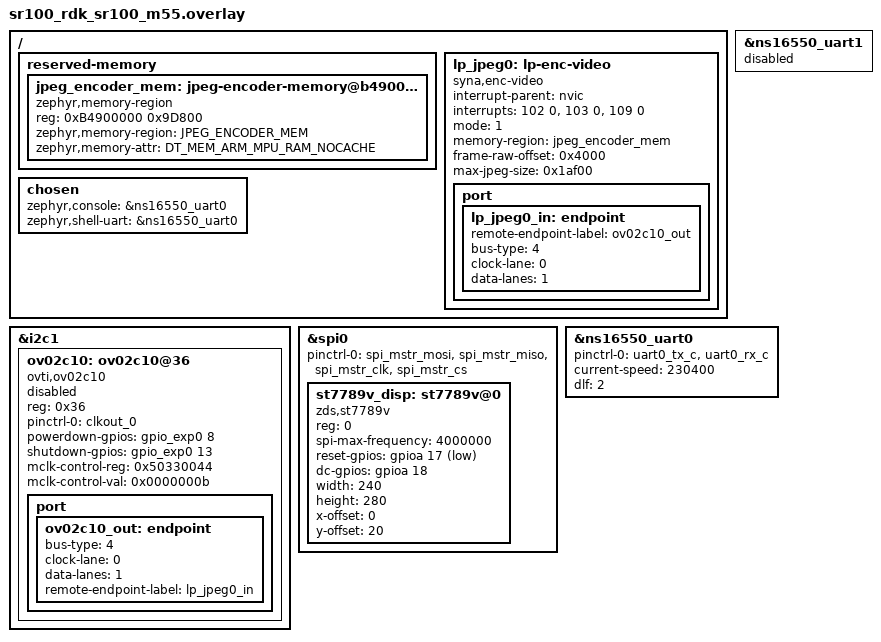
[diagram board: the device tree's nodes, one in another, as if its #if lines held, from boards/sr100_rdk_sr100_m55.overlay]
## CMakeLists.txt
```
cmake_minimum_required(VERSION 3.20.0)
list(APPEND DTS_ROOT ${CMAKE_CURRENT_SOURCE_DIR})
find_package(Zephyr REQUIRED HINTS $ENV{ZEPHYR_BASE})
project(camera_jpeg_encode)

target_sources(app PRIVATE
	src/main.c
	src/tft_still.c
	src/tjpgd.c
)
target_include_directories(app PRIVATE src)
```

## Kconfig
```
# Copyright (c) 2026 Synaptics Incorporated
# SPDX-License-Identifier: Apache-2.0
#
# Lab C4: camera -> hardware JPEG encoder. Based verbatim on the SDK's
# samples/drivers/video/enc sample (live sensor mode, mode=0).

mainmenu "Camera JPEG Encode Lab (SR110)"

source "Kconfig.zephyr"

menu "Camera JPEG Encode Lab"

endmenu
```

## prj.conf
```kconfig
CONFIG_CONSOLE=y
CONFIG_PRINTK=y
CONFIG_LOG=y
CONFIG_LOG_MODE_IMMEDIATE=y
# Avoid Kconfig warnings from board defaults pulling in I2C shell options.
CONFIG_I2C_SHELL=n
CONFIG_FPU=y
CONFIG_I2C=y
CONFIG_GPIO=y
CONFIG_PINCTRL=y
CONFIG_VIDEO=y
CONFIG_VIDEO_SYNA_ENC=y
CONFIG_VIDEO_SYNA_MIPI=n
CONFIG_VIDEO_INIT_PRIORITY=90

# Two 128 KiB buffers + overhead (give headroom).
CONFIG_VIDEO_BUFFER_POOL_HEAP_SIZE=524288

CONFIG_MAIN_STACK_SIZE=4096

# TFT still preview (ST7789V3 raw-SPI driver, reused from Lab C3) - SPI0
# for the panel, GPIO for reset/dc pins. Console is moved to UART0 alt
# pins by the board overlay because SPI0 shares pads with UART1 (see
# the lab doc) - same tradeoff as Lab C3.
CONFIG_SPI=y
```

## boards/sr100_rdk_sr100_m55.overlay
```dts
/*
 * Lab C4 (Camera JPEG Encode + TFT Still Preview) - SR110 (sr100_rdk/sr100/m55)
 *
 * This overlay combines two independent pieces:
 *
 * 1) JPEG hardware encoder pipeline (unchanged from the SDK's
 *    samples/drivers/video/enc sample) - the sensor's CSI output is
 *    connected directly to the encoder node (lp_jpeg0), bypassing
 *    video_syna0 entirely. See the lab doc for why.
 *
 * 2) ST7789V3 TFT over SPI0, reusing Lab C3's confirmed-working
 *    config verbatim, to show the just-encoded JPEG as a still image
 *    after it is decoded back to RGB565 on-device. SPI0's MOSI/MISO
 *    pads are physically shared with the M55's default console UART
 *    (UART1, GPIO23/24), so the console is moved to UART0's alternate
 *    pin group here, exactly like Lab C3 - an external USB-TTL
 *    adapter is needed to see console output (GPIO44/45, J24 pins
 *    13/14).
 */

#include <zephyr/dt-bindings/gpio/gpio.h>
#include <zephyr/dt-bindings/memory-attr/memory-attr-arm.h>

/ {
	reserved-memory {
		#address-cells = <1>;
		#size-cells = <1>;
		ranges;

		jpeg_encoder_mem: jpeg-encoder-memory@b4900000 {
			compatible = "zephyr,memory-region", "mmio-sram";
			reg = <0xB4900000 0x9D800>; /* 0x4000 + 0x7e900 (960x540 RAW8) + 0x1af00 (max JPEG) */
			zephyr,memory-region = "JPEG_ENCODER_MEM";
			zephyr,memory-attr = <DT_MEM_ARM_MPU_RAM_NOCACHE>;
		};
	};

	lp_jpeg0: lp-enc-video {
		compatible = "syna,enc-video";
		status = "okay";
		interrupt-parent = <&nvic>;
		/*
		 * This JPEG encoder flow uses all three underlying IRQ lines:
		 * 102 = FRAME_PROCESSING_DONE, 103 = FMIN1_FRAME_STORED,
		 * 109 = c0 / status events.
		 */
		interrupts = <102 0>, <103 0>, <109 0>;
		interrupt-names = "frame-done", "fmin1-stored", "status";

		/*
		 * Build-time selectable mode.
		 *
		 * Define ENC_MEMORY_INPUT via DTS_EXTRA_CPPFLAGS to switch the
		 * encoder to reserved-memory input mode (static raw in memory).
		 * See "추가로 알면 좋은 내용" in the lab doc for how to try this.
		 */
#ifdef ENC_MEMORY_INPUT
		mode = <1>; /* memory-input mode */
#else
		mode = <0>; /* live sensor mode - default for this lab */
#endif

		/* JPEG encoder reserved memory for raw input and JPEG output buffers. */
		memory-region = <&jpeg_encoder_mem>;
		/* Reserve programmer area (SRSDK default is 0x4000). */
		frame-raw-offset = <0x4000>;

#ifdef ENC_MEMORY_INPUT
		/* Raw input (960x540 = 0x7E900 bytes) starts at frame-raw-offset. */
		max-jpeg-size = <0x1af00>;
#else
		max-jpeg-size = <0x20000>;
#endif

		port {
			lp_jpeg0_in: endpoint {
				remote-endpoint-label = "ov02c10_out";
				bus-type = <4>;
				clock-lane = <0>;
				data-lanes = <1>;
			};
		};

	};
};

	&i2c1 {
		ov02c10: ov02c10@36 {
			compatible = "ovti,ov02c10";
			reg = <0x36>;
#ifdef ENC_MEMORY_INPUT
			status = "disabled";
#else
			status = "okay";
#endif

		pinctrl-0 = <&clkout_0>;
		pinctrl-names = "default";

		powerdown-gpios = <&gpio_exp0 8 GPIO_ACTIVE_HIGH>;
		shutdown-gpios = <&gpio_exp0 13 GPIO_ACTIVE_HIGH>;

		mclk-control-reg = <0x50330044>;
		mclk-control-val = <0x0000000b>;

		port {
			ov02c10_out: endpoint {
				bus-type = <4>;
				clock-lane = <0>;
				data-lanes = <1>;
				remote-endpoint-label = "lp_jpeg0_in";
			};
		};
	};
};

/* --- TFT still-preview display (Lab C3 config, reused verbatim) --- */

&spi0 {
	#address-cells = <1>;
	#size-cells = <0>;
	status = "okay";
	pinctrl-0 = <&spi_mstr_mosi &spi_mstr_miso &spi_mstr_clk &spi_mstr_cs>;
	pinctrl-names = "default";

	st7789v_disp: st7789v@0 {
		compatible = "zds,st7789v";
		reg = <0>;
		spi-max-frequency = <4000000>;
		reset-gpios = <&gpioa 17 GPIO_ACTIVE_LOW>;  /* SoC GPIO17, J24 pin 3 - through level shifter */
		dc-gpios = <&gpioa 18 GPIO_ACTIVE_HIGH>;    /* SoC GPIO18, J24 pin 4 - through level shifter */
		width = <240>;
		height = <280>;
		x-offset = <0>;
		y-offset = <20>;
	};
};

&ns16550_uart1 {
	status = "disabled";
};

&ns16550_uart0 {
	pinctrl-0 = <&uart0_tx_c &uart0_rx_c>;
	pinctrl-names = "default";
	current-speed = <230400>;
	dlf = <2>;
	status = "okay";
};

/ {
	chosen {
		zephyr,console = &ns16550_uart0;
		zephyr,shell-uart = &ns16550_uart0;
	};
};
```

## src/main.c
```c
/*
 * Copyright (c) 2026 Synaptics Incorporated
 *
 * SPDX-License-Identifier: Apache-2.0
 *
 * Lab C4 (Camera JPEG Encode + TFT Still Preview): this is the SDK's
 * samples/drivers/video/enc sample (live sensor mode) with one
 * addition - after the hardware encoder produces a JPEG frame, it is
 * decoded back to RGB565 on-device and shown as a still image on the
 * ST7789V3 TFT (see tft_still.c/.h). Everything else below is
 * unmodified from the original sample.
 */

#include <errno.h>
#include <stdint.h>
#include <string.h>

#include <zephyr/cache.h>
#include <zephyr/device.h>
#include <zephyr/devicetree.h>
#include <zephyr/drivers/video.h>
#include <zephyr/kernel.h>
#include <zephyr/logging/log.h>
#include <zephyr/sys/barrier.h>
#include <zephyr/sys/util.h>
#include <zephyr/video/video.h>

#include "tft_still.h"

LOG_MODULE_REGISTER(enc_video_sample, LOG_LEVEL_INF);

#define TS_LOG(stage) LOG_INF("[TS] %s uptime_ms=%lld", stage, (long long)k_uptime_get())

static inline int64_t app_elapsed_ms(int64_t start_ms)
{
	return k_uptime_get() - start_ms;
}

#define ENC_NODE DT_NODELABEL(lp_jpeg0)

#if !DT_NODE_EXISTS(ENC_NODE)
#error "No lp_jpeg0 devicetree node found"
#endif

#if !DT_NODE_HAS_COMPAT(ENC_NODE, syna_enc_video)
#error "lp_jpeg0 must use compatible = \"syna,enc-video\""
#endif

#define APP_MODE_SENSOR_TO_MEMORY 0U
#define APP_MODE_MEMORY_INPUT 1U
#define APP_PIPELINE_MODE DT_PROP_OR(ENC_NODE, mode, APP_MODE_SENSOR_TO_MEMORY)

#define APP_NUM_BUFS 2U
#define APP_JPEG_BUF_ALIGN 64U
#define APP_MAX_JPEG_BYTES (128U * 1024U)
#define APP_DEQUEUE_TIMEOUT K_SECONDS(5)

#define APP_LIVE_WIDTH 480U
#define APP_LIVE_HEIGHT 270U

#define APP_MEMORY_INPUT_WIDTH 960U
#define APP_MEMORY_INPUT_HEIGHT 540U
#define APP_MEMORY_INPUT_RAW_SIZE ((size_t)APP_MEMORY_INPUT_WIDTH * (size_t)APP_MEMORY_INPUT_HEIGHT)

#define APP_MEM_REGION_PRESENT DT_NODE_HAS_PROP(ENC_NODE, memory_region)
BUILD_ASSERT(APP_MEM_REGION_PRESENT,
	     "JPEG encoder sample requires a memory-region devicetree phandle");
#if APP_MEM_REGION_PRESENT
#define APP_MEM_NODE DT_PHANDLE(ENC_NODE, memory_region)
#define APP_MEM_BASE ((uintptr_t)DT_REG_ADDR(APP_MEM_NODE))
#define APP_MEM_SIZE ((size_t)DT_REG_SIZE(APP_MEM_NODE))
#else
#define APP_MEM_BASE ((uintptr_t)0U)
#define APP_MEM_SIZE 0U
#endif

#define APP_RAW_OFFSET ((size_t)DT_PROP_OR(ENC_NODE, frame_raw_offset, 0))

static uint8_t app_jpeg_buf_mem[APP_NUM_BUFS][APP_MAX_JPEG_BYTES] __aligned(APP_JPEG_BUF_ALIGN);
static struct video_buffer app_jpeg_vbufs[APP_NUM_BUFS];

#if IS_ENABLED(CONFIG_CACHE_MANAGEMENT) && IS_ENABLED(CONFIG_DCACHE)
static void enc_mem_flush(uintptr_t addr, size_t size)
{
	int ret;

	if (size == 0U) {
		return;
	}

	ret = sys_cache_data_flush_range((void *)addr, size);
	if (ret != 0) {
		LOG_WRN("Encoder memory cache flush failed ret=%d addr=%p size=%u",
			ret, (void *)addr, (unsigned int)size);
	}
	barrier_dsync_fence_full();
}
#else
static void enc_mem_flush(uintptr_t addr, size_t size)
{
	ARG_UNUSED(addr);
	ARG_UNUSED(size);
}
#endif

/* Return a human-readable name for the selected run mode. */
static const char *mode_name(uint32_t mode)
{
	if (mode == APP_MODE_MEMORY_INPUT) {
		return "enc-memory-input";
	}

	return "live-to-memory";
}

/* Drain any returned buffers after stopping the stream. */
static void drain_buffers(const struct device *dev)
{
	struct video_buffer *vbuf = NULL;

	while ((video_dequeue(dev, &vbuf, K_NO_WAIT) == 0) && (vbuf != NULL)) {
		vbuf->bytesused = 0U;
	}
}

/* Video helpers */

/*
 * Configure the JPEG output format.
 *
 * The negotiated `jpeg_fmt->size` is the required output-buffer capacity.
 * The actual JPEG size is returned later in `video_buffer.bytesused`.
 */
static int enc_configure(const struct device *enc,
			 struct video_format *jpeg_fmt,
			 uint32_t width,
			 uint32_t height)
{
	int ret;

	*jpeg_fmt = (struct video_format) {
		.type = VIDEO_BUF_TYPE_OUTPUT,
		.pixelformat = VIDEO_PIX_FMT_JPEG,
		.width = width,
		.height = height,
	};

	ret = video_set_format(enc, jpeg_fmt);
	LOG_INF("enc video_set_format ret=%d capacity=%u pitch=%u (%ux%u)",
		ret, jpeg_fmt->size, jpeg_fmt->pitch,
		jpeg_fmt->width, jpeg_fmt->height);
	return ret;
}

/* Allocate and enqueue destination buffers for JPEG output. */
static int jpeg_buffers_queue(const struct device *enc,
			      const struct video_format *jpeg_fmt)
{
	struct video_caps caps = {
		.type = VIDEO_BUF_TYPE_OUTPUT,
	};
	size_t align = APP_JPEG_BUF_ALIGN;
	int ret;

	if ((jpeg_fmt == NULL) || (jpeg_fmt->size > APP_MAX_JPEG_BYTES)) {
		LOG_ERR("JPEG buffer pool too small: required capacity=%u max=%u",
			jpeg_fmt != NULL ? jpeg_fmt->size : 0U,
			(unsigned int)APP_MAX_JPEG_BYTES);
		return -EINVAL;
	}

	ret = video_get_caps(enc, &caps);
	LOG_INF("enc video_get_caps ret=%d min_vbuf=%u align=%zu",
		ret, caps.min_vbuf_count, caps.buf_align);
	if (ret != 0) {
		return ret;
	}

	if (APP_NUM_BUFS < caps.min_vbuf_count) {
		LOG_ERR("APP_NUM_BUFS too small: available=%u required(min_vbuf_count)=%u",
			(unsigned int)APP_NUM_BUFS, caps.min_vbuf_count);
		return -EINVAL;
	}

	if (caps.buf_align != 0U) {
		align = caps.buf_align;
	}

	if (align > APP_JPEG_BUF_ALIGN) {
		LOG_ERR("JPEG buffer alignment too small: required=%zu available=%u",
			align, (unsigned int)APP_JPEG_BUF_ALIGN);
		return -EINVAL;
	}

	for (size_t i = 0; i < APP_NUM_BUFS; i++) {
		struct video_buffer *vbuf = &app_jpeg_vbufs[i];
		uint16_t imported_idx;

		memset(vbuf, 0, sizeof(*vbuf));
		vbuf->type = VIDEO_BUF_TYPE_OUTPUT;
		vbuf->buffer = app_jpeg_buf_mem[i];
		vbuf->size = APP_MAX_JPEG_BYTES;

		ret = video_import_buffer(vbuf->buffer, vbuf->size, &imported_idx);
		if (ret != 0) {
			LOG_ERR("enc video_import_buffer[%u] failed: %d", (unsigned int)i, ret);
			return ret;
		}
		vbuf->index = imported_idx;

		LOG_INF("enc app_buf[%u] addr=%p size=%u align=%zu",
			(unsigned int)i, vbuf->buffer, (unsigned int)vbuf->size, align);

		ret = video_enqueue(enc, vbuf);
		LOG_INF("enc video_enqueue[%u] ret=%d", (unsigned int)i, ret);
		if (ret != 0) {
			return ret;
		}
	}

	return 0;
}

/* Static reserved-memory input frame generation */

static uint8_t bayer_from_rgb(uint16_t x, uint16_t y, uint8_t red,
			      uint8_t green, uint8_t blue)
{
	if (((y & 1U) == 0U) && ((x & 1U) == 0U)) {
		return blue;
	}

	if (((y & 1U) == 1U) && ((x & 1U) == 1U)) {
		return red;
	}

	return green;
}

static void fill_bayer_pattern(uint8_t *dst, uint16_t width, uint16_t height)
{
	static const uint8_t color_bars[][3] = {
		{ 0x00, 0x00, 0x00 }, /* black */
		{ 0x00, 0x00, 0xff }, /* blue */
		{ 0x00, 0xff, 0xff }, /* cyan */
		{ 0x00, 0xff, 0x00 }, /* green */
		{ 0xff, 0x00, 0xff }, /* magenta */
		{ 0xff, 0x00, 0x00 }, /* red */
		{ 0xff, 0xff, 0x00 }, /* yellow */
		{ 0xff, 0xff, 0xff }, /* white */
	};
	const uint16_t bar_count = ARRAY_SIZE(color_bars);

	for (uint16_t y = 0; y < height; y++) {
		for (uint16_t x = 0; x < width; x++) {
			uint16_t bar = (uint16_t)(((uint32_t)x * bar_count) /
						  MAX(width, (uint16_t)1U));
			uint8_t red;
			uint8_t green;
			uint8_t blue;

			if (bar >= bar_count) {
				bar = bar_count - 1U;
			}

			red = color_bars[bar][0];
			green = color_bars[bar][1];
			blue = color_bars[bar][2];

			if ((y > (height * 3U) / 4U) &&
			    (((x / 16U) & 1U) != ((y / 16U) & 1U))) {
				red >>= 1;
				green >>= 1;
				blue >>= 1;
			}

			dst[(size_t)y * width + x] =
				bayer_from_rgb(x, y, red, green, blue);
		}
	}
}

/* Seed the raw reserved-memory input frame into reserved memory based on DTS offsets. */
static int seed_memory_frame(void)
{
	uint8_t *raw;
	int64_t seed_start_ms = k_uptime_get();

	if ((APP_MEM_BASE == 0U) || (APP_MEM_SIZE == 0U)) {
		LOG_ERR("Encoder memory base/size missing in DTS");
		return -EINVAL;
	}

	if ((APP_MEMORY_INPUT_RAW_SIZE > APP_MEM_SIZE) ||
	    (APP_RAW_OFFSET > (APP_MEM_SIZE - APP_MEMORY_INPUT_RAW_SIZE))) {
		LOG_ERR("reserved-memory raw source buffer does not fit reserved memory");
		return -ENOMEM;
	}

	/*
	 * In mode=1 (memory-input), the driver places the JPEG output region after
	 * the raw input region. The application only needs to populate the raw
	 * input frame at frame-raw-offset.
	 */
	raw = (uint8_t *)(uintptr_t)(APP_MEM_BASE + APP_RAW_OFFSET);
	fill_bayer_pattern(raw, APP_MEMORY_INPUT_WIDTH, APP_MEMORY_INPUT_HEIGHT);
	enc_mem_flush((uintptr_t)raw, APP_MEMORY_INPUT_RAW_SIZE);

	LOG_INF("Seeded encoder-memory raw Bayer color-bar pattern at %p size=%u (%ux%u)",
		raw, (unsigned int)APP_MEMORY_INPUT_RAW_SIZE,
		APP_MEMORY_INPUT_WIDTH, APP_MEMORY_INPUT_HEIGHT);
	LOG_INF("Input frame seeded in encoder RAM in %lld ms",
		(long long)app_elapsed_ms(seed_start_ms));
	return 0;
}

/* Capture execution paths */

static int wait_and_report(const struct device *enc, uint32_t mode, int64_t encode_start_ms)
{
	struct video_buffer *out = NULL;
	int ret;

	ARG_UNUSED(mode);
	TS_LOG("ENC_JPEG_WAIT_START");
	ret = video_dequeue(enc, &out, APP_DEQUEUE_TIMEOUT);
	LOG_INF("enc video_dequeue ret=%d", ret);
	if (ret != 0) {
		LOG_ERR("failed to dequeue JPEG output ret=%d", ret);
		return ret;
	}

	LOG_INF("Frame captured at addr=%p bytesused=%u",
		out->buffer, (unsigned int)out->bytesused);
	TS_LOG("ENC_JPEG_DONE");
	LOG_INF("Encoder done in %lld ms (jpeg=%u bytes, mode=%s)",
		(long long)app_elapsed_ms(encode_start_ms),
		(unsigned int)out->bytesused, mode_name(mode));

	if (out->bytesused != 0U) {
#if IS_ENABLED(CONFIG_CACHE_MANAGEMENT) && IS_ENABLED(CONFIG_DCACHE)
		(void)sys_cache_data_flush_range(out->buffer, out->bytesused);
#endif
		LOG_INF("Dump JPEG from %p (%p + %u)",
			out->buffer, out->buffer, (unsigned int)out->bytesused);

		/*
		 * New in this lab (vs. the original SDK sample): decode the
		 * JPEG we just produced and show it as a still image on the
		 * TFT, while the buffer is still valid (it gets recycled by
		 * cleanup_capture()/drain_buffers() right after we return).
		 */
		int disp_ret = tft_still_show_jpeg(out->buffer, out->bytesused);

		if (disp_ret != 0) {
			LOG_WRN("tft_still_show_jpeg failed ret=%d (display wiring/decode issue?)",
				disp_ret);
		}
	}

	return 0;
}

/* Stop streams and return any queued buffers back to the app. */
static void cleanup_capture(const struct device *enc,
			    bool jpeg_buffers_queued,
			    bool enc_started)
{
	if (enc_started) {
		/*
		 * The wrapper owns live-path shutdown ordering in mode 0 and
		 * stops the live input before dismantling the JPEG encoder pipeline.
		 */
		(void)video_stream_stop(enc, VIDEO_BUF_TYPE_OUTPUT);
	} else if (jpeg_buffers_queued) {
		/*
		 * If stream start never succeeded, use flush(cancel=true) to reclaim
		 * any queued output buffers without issuing stream_stop().
		 */
		(void)video_flush(enc, true);
	}

	if (jpeg_buffers_queued) {
		drain_buffers(enc);
	}
}

/* Run mode 0: live input-to-memory capture through the JPEG encoder. */
static int run_live_mode(const struct device *enc)
{
	struct video_format jpeg_fmt;
	bool jpeg_buffers_queued = false;
	bool enc_started = false;
	int64_t encoder_phase_start_ms = k_uptime_get();
	int ret;

	ret = enc_configure(enc, &jpeg_fmt,
			    APP_LIVE_WIDTH, APP_LIVE_HEIGHT);
	if (ret != 0) {
		LOG_ERR("JPEG encoder format configuration failed ret=%d", ret);
		goto out;
	}

	ret = jpeg_buffers_queue(enc, &jpeg_fmt);
	if (ret != 0) {
		LOG_ERR("failed to prepare JPEG encoder buffers ret=%d", ret);
		goto out;
	}
	jpeg_buffers_queued = true;

	ret = video_stream_start(enc, VIDEO_BUF_TYPE_OUTPUT);
	LOG_INF("enc video_stream_start ret=%d", ret);
	if (ret != 0) {
		LOG_ERR("JPEG encoder stream start failed ret=%d", ret);
		goto out;
	}
	enc_started = true;
	LOG_INF("Encoder stream started in %lld ms",
		(long long)app_elapsed_ms(encoder_phase_start_ms));

	ret = wait_and_report(enc, APP_MODE_SENSOR_TO_MEMORY, k_uptime_get());
	if (ret != 0) {
		LOG_ERR("live-mode JPEG capture failed ret=%d", ret);
	} else {
		LOG_INF("Live-mode encode flow completed in %lld ms",
			(long long)app_elapsed_ms(encoder_phase_start_ms));
	}

out:
	cleanup_capture(enc, jpeg_buffers_queued, enc_started);
	return ret;
}

/* Run mode 1: reserved-memory input test pattern through the JPEG encoder. */
static int run_memory_mode(const struct device *enc)
{
	struct video_format jpeg_fmt;
	bool jpeg_buffers_queued = false;
	bool enc_started = false;
	int64_t encoder_phase_start_ms = k_uptime_get();
	int ret;

	ret = enc_configure(enc, &jpeg_fmt,
			    APP_MEMORY_INPUT_WIDTH, APP_MEMORY_INPUT_HEIGHT);
	if (ret != 0) {
		LOG_ERR("JPEG encoder format configuration failed ret=%d", ret);
		return ret;
	}

	ret = seed_memory_frame();
	if (ret != 0) {
		LOG_ERR("failed to seed reserved-memory input frame ret=%d", ret);
		return ret;
	}

	ret = jpeg_buffers_queue(enc, &jpeg_fmt);
	if (ret != 0) {
		LOG_ERR("failed to prepare JPEG encoder buffers ret=%d", ret);
		goto out;
	}
	jpeg_buffers_queued = true;

	ret = video_stream_start(enc, VIDEO_BUF_TYPE_OUTPUT);
	LOG_INF("enc video_stream_start ret=%d", ret);
	if (ret != 0) {
		LOG_ERR("JPEG encoder stream start failed ret=%d", ret);
		goto out;
	}
	enc_started = true;
	LOG_INF("Encoder stream started in %lld ms",
		(long long)app_elapsed_ms(encoder_phase_start_ms));

	/*
	 * Note: in this mode the source is a synthetic 960x540 pattern,
	 * not this lab's fixed 480x270 live size, so tft_still_show_jpeg()
	 * (sized for 480x270 -> 240x135 decode) will log a size mismatch
	 * warning and skip the display step - only mode=0 (the default)
	 * drives the TFT still preview.
	 */
	ret = wait_and_report(enc, APP_MODE_MEMORY_INPUT, k_uptime_get());
	if (ret != 0) {
		LOG_ERR("reserved-memory JPEG capture failed ret=%d", ret);
	} else {
		LOG_INF("Memory-input encode flow completed in %lld ms",
			(long long)app_elapsed_ms(encoder_phase_start_ms));
	}

out:
	cleanup_capture(enc, jpeg_buffers_queued, enc_started);
	return ret;
}

/* Application entry point: select the devicetree-configured run mode. */
int main(void)
{
	const struct device *enc = DEVICE_DT_GET(ENC_NODE);
	uint32_t mode = APP_PIPELINE_MODE;
	int64_t app_start_ms = k_uptime_get();
	int ret;

	TS_LOG("ENC_MAIN_ENTER");
	LOG_INF("JPEG encoder validator start (%s, mode=%u)",
		mode_name(mode), (unsigned int)mode);

	tft_still_init();

	if (!device_is_ready(enc)) {
		LOG_ERR("JPEG encoder device not ready");
		return -ENODEV;
	}

	if (mode == APP_MODE_MEMORY_INPUT) {
		ret = run_memory_mode(enc);
	} else if (mode == APP_MODE_SENSOR_TO_MEMORY) {
		ret = run_live_mode(enc);
	} else {
		LOG_ERR("unsupported sample mode %u", (unsigned int)mode);
		return -EINVAL;
	}

	if (ret != 0) {
		LOG_ERR("JPEG encoder validator failed (%s, ret=%d)",
			mode_name(mode), ret);
	}
	LOG_INF("Sample completed in %lld ms from start",
		(long long)app_elapsed_ms(app_start_ms));
	LOG_INF("JPEG encoder validator done ret=%d", ret);
	return ret;
}
```

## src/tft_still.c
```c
/*
 * Lab C4 (Camera JPEG Encode + TFT Still Preview).
 *
 * The low-level ST7789V3 init sequence, SPI0 8-byte FIFO chunking
 * (st7789_send()) and addr-window setup below are taken verbatim from
 * ai_labs/03_sensor_anomaly's tft_status.c / Lab C3's tft_preview.c -
 * see those files for the extended commentary on why a raw driver is
 * used instead of Zephyr's in-tree "sitronix,st7789v" driver, and why
 * SPI0 writes must be chunked to 8 bytes.
 *
 * What is new here is tft_still_show_jpeg(): instead of drawing text
 * (03_sensor_anomaly) or a continuously-refreshed grayscale
 * debayer-lite preview (Lab C3), this decodes the still JPEG the
 * hardware encoder just produced - using the vendored TJpgDec decoder
 * (tjpgd.c, see its header for license/version) - and displays it
 * once as a real color image.
 */
#include <errno.h>
#include <string.h>

#include <zephyr/kernel.h>
#include <zephyr/device.h>
#include <zephyr/devicetree.h>
#include <zephyr/drivers/spi.h>
#include <zephyr/drivers/gpio.h>
#include <zephyr/sys/printk.h>
#include <zephyr/sys/util.h>
#include <stdbool.h>

#include "tft_still.h"
#include "tjpgd.h"

#define DISP_NODE DT_NODELABEL(st7789v_disp)

#define PANEL_WIDTH   DT_PROP(DISP_NODE, width)
#define PANEL_HEIGHT  DT_PROP(DISP_NODE, height)
#define X_OFFSET      DT_PROP(DISP_NODE, x_offset)
#define Y_OFFSET      DT_PROP(DISP_NODE, y_offset)

#define ST7789_SWRESET  0x01
#define ST7789_SLPOUT   0x11
#define ST7789_COLMOD   0x3A
#define ST7789_MADCTL   0x36
#define ST7789_INVON    0x21
#define ST7789_NORON    0x13
#define ST7789_DISPON   0x29
#define ST7789_CASET    0x2A
#define ST7789_RASET    0x2B
#define ST7789_RAMWR    0x2C
#define ST7789_PORCTRL  0xB2
#define ST7789_GCTRL    0xB7
#define ST7789_VCOMS    0xBB
#define ST7789_LCMCTRL  0xC0
#define ST7789_VDVVRHEN 0xC2
#define ST7789_VRHS     0xC3
#define ST7789_VDVS     0xC4
#define ST7789_FRCTRL2  0xC6
#define ST7789_PWCTRL1  0xD0
#define ST7789_PVGAMCTRL 0xE0
#define ST7789_NVGAMCTRL 0xE1

#define COLOR_BLACK   0x0000

#define ST7789_CHUNK_BYTES 8

static const struct spi_dt_spec spi_spec =
	SPI_DT_SPEC_GET(DISP_NODE, SPI_WORD_SET(8) | SPI_TRANSFER_MSB, 0);
static const struct gpio_dt_spec reset_spec = GPIO_DT_SPEC_GET(DISP_NODE, reset_gpios);
static const struct gpio_dt_spec dc_spec = GPIO_DT_SPEC_GET(DISP_NODE, dc_gpios);

static bool tft_ready;

static int st7789_send(int dc_value, const uint8_t *data, size_t len)
{
	int ret;

	gpio_pin_set_dt(&dc_spec, dc_value);

	while (len) {
		size_t chunk = MIN(len, ST7789_CHUNK_BYTES);
		struct spi_buf buf = { .buf = (void *)data, .len = chunk };
		struct spi_buf_set set = { .buffers = &buf, .count = 1 };

		ret = spi_write_dt(&spi_spec, &set);
		if (ret) {
			return ret;
		}
		data += chunk;
		len -= chunk;
	}
	return 0;
}

static int st7789_write_cmd(uint8_t cmd)
{
	return st7789_send(0, &cmd, 1);
}

static int st7789_write_data(const uint8_t *data, size_t len)
{
	return st7789_send(1, data, len);
}

static int st7789_reset(void)
{
	int ret = gpio_pin_configure_dt(&reset_spec, GPIO_OUTPUT_INACTIVE);

	if (ret) {
		return ret;
	}
	k_sleep(K_MSEC(10));
	gpio_pin_set_dt(&reset_spec, 1);
	k_sleep(K_MSEC(10));
	gpio_pin_set_dt(&reset_spec, 0);
	k_sleep(K_MSEC(150));
	return 0;
}

struct st7789_init_cmd {
	uint8_t cmd;
	uint8_t num_args;
	uint8_t args[16];
	uint16_t delay_ms;
};

static const struct st7789_init_cmd init_seq[] = {
	{ ST7789_SWRESET,   0, {0}, 150 },
	{ ST7789_SLPOUT,    0, {0}, 255 },
	{ ST7789_COLMOD,    1, {0x55}, 10 },
	{ ST7789_PORCTRL,   5, {0x0C, 0x0C, 0x00, 0x33, 0x33}, 0 },
	{ ST7789_GCTRL,     1, {0x35}, 0 },
	{ ST7789_VCOMS,     1, {0x28}, 0 },
	{ ST7789_LCMCTRL,   1, {0x0C}, 0 },
	{ ST7789_VDVVRHEN,  2, {0x01, 0xFF}, 0 },
	{ ST7789_VRHS,      1, {0x10}, 0 },
	{ ST7789_VDVS,      1, {0x20}, 0 },
	{ ST7789_FRCTRL2,   1, {0x0F}, 0 },
	{ ST7789_PWCTRL1,   2, {0xA4, 0xA1}, 0 },
	{ ST7789_MADCTL,    1, {0x08}, 0 },  /* 0x08 = BGR order (this panel; 0x00 is RGB) - see ai_labs/03_sensor_anomaly */
	{ ST7789_INVON,     0, {0}, 10 },
	{ ST7789_PVGAMCTRL, 14, {0xD0, 0x00, 0x02, 0x07, 0x0A, 0x28, 0x32, 0x44,
				 0x42, 0x06, 0x0E, 0x12, 0x14, 0x17}, 0 },
	{ ST7789_NVGAMCTRL, 14, {0xD0, 0x00, 0x02, 0x07, 0x05, 0x25, 0x2D, 0x44,
				 0x45, 0x10, 0x0E, 0x12, 0x13, 0x17}, 0 },
	{ ST7789_NORON,     0, {0}, 10 },
	{ ST7789_DISPON,    0, {0}, 100 },
};

static int st7789_init(void)
{
	for (size_t i = 0; i < ARRAY_SIZE(init_seq); i++) {
		int ret = st7789_write_cmd(init_seq[i].cmd);

		if (ret) return ret;
		if (init_seq[i].num_args) {
			ret = st7789_write_data(init_seq[i].args, init_seq[i].num_args);
			if (ret) return ret;
		}
		if (init_seq[i].delay_ms) {
			k_sleep(K_MSEC(init_seq[i].delay_ms));
		}
	}
	return 0;
}

static int st7789_set_addr_window(uint16_t x0, uint16_t y0, uint16_t x1, uint16_t y1)
{
	uint16_t xs = x0 + X_OFFSET, xe = x1 + X_OFFSET;
	uint16_t ys = y0 + Y_OFFSET, ye = y1 + Y_OFFSET;
	uint8_t caset[4] = { xs >> 8, xs & 0xFF, xe >> 8, xe & 0xFF };
	uint8_t raset[4] = { ys >> 8, ys & 0xFF, ye >> 8, ye & 0xFF };
	int ret;

	ret = st7789_write_cmd(ST7789_CASET);
	if (ret) return ret;
	ret = st7789_write_data(caset, sizeof(caset));
	if (ret) return ret;
	ret = st7789_write_cmd(ST7789_RASET);
	if (ret) return ret;
	ret = st7789_write_data(raset, sizeof(raset));
	if (ret) return ret;
	return st7789_write_cmd(ST7789_RAMWR);
}

static int st7789_fill_rect(uint16_t x, uint16_t y, uint16_t w, uint16_t h, uint16_t color)
{
	uint8_t row[PANEL_WIDTH * 2];
	int ret;

	ret = st7789_set_addr_window(x, y, x + w - 1, y + h - 1);
	if (ret) return ret;

	for (uint16_t i = 0; i < w; i++) {
		row[i * 2] = color >> 8;
		row[i * 2 + 1] = color & 0xFF;
	}
	for (uint16_t line = 0; line < h; line++) {
		ret = st7789_write_data(row, (size_t)w * 2);
		if (ret) return ret;
	}
	return 0;
}

void tft_still_init(void)
{
	int ret;

	if (!spi_is_ready_dt(&spi_spec) || !gpio_is_ready_dt(&reset_spec) ||
	    !gpio_is_ready_dt(&dc_spec)) {
		printk("tft_still: SPI/GPIO not ready, display disabled\n");
		return;
	}

	ret = gpio_pin_configure_dt(&dc_spec, GPIO_OUTPUT_INACTIVE);
	if (ret) {
		printk("tft_still: dc-gpio configure failed: %d, display disabled\n", ret);
		return;
	}

	if (st7789_reset() || st7789_init()) {
		printk("tft_still: reset/init failed (check wiring/level shifter), display disabled\n");
		return;
	}
	st7789_fill_rect(0, 0, PANEL_WIDTH, PANEL_HEIGHT, COLOR_BLACK);
	tft_ready = true;
}

/*
 * ---- JPEG decode ----
 *
 * This lab's live capture is fixed at 480x270 (see APP_LIVE_WIDTH/
 * APP_LIVE_HEIGHT in main.c). TJpgDec is asked to decode at scale=1
 * (see tjpgdcnf.h: JD_USE_SCALE=1), which halves both dimensions
 * *during* decode (cheaper than decoding full-size and downscaling
 * afterwards) - so the decoded image lands directly at 240x135,
 * already close to the panel's resolution.
 */
#define DEC_WIDTH  240U
#define DEC_HEIGHT 135U
#define JD_SCALE   1U /* 1/2 size: matches DEC_WIDTH/DEC_HEIGHT above */

/* TJpgDec's own required workspace for Huffman/IDCT tables etc. -
 * ChaN's documentation suggests ~3.1 KB is enough for most images;
 * this leaves some headroom. If jd_prepare()/jd_decomp() ever returns
 * JDR_MEM1, raise this.
 */
#define JD_WORK_SIZE 4096U

static uint8_t jd_work[JD_WORK_SIZE];
/* Decoded RGB565 framebuffer, one uint16_t per pixel. */
static uint16_t g_decode_fb[DEC_WIDTH * DEC_HEIGHT];

struct jpeg_input_ctx {
	const uint8_t *data;
	size_t size;
	size_t pos;
};

/* TJpgDec input callback: pulls up to ndata bytes from our in-memory
 * JPEG buffer. buf may be NULL (TJpgDec asking to skip bytes without
 * reading them) - memcpy is skipped in that case.
 */
static size_t jpeg_input_func(JDEC *jd, uint8_t *buf, size_t ndata)
{
	struct jpeg_input_ctx *ctx = (struct jpeg_input_ctx *)jd->device;
	size_t avail = ctx->size - ctx->pos;
	size_t n = MIN(ndata, avail);

	if (buf != NULL && n != 0U) {
		memcpy(buf, ctx->data + ctx->pos, n);
	}
	ctx->pos += n;
	return n;
}

/* TJpgDec output callback: called once per decoded MCU block with a
 * packed RGB565 bitmap (JD_FORMAT=1, see tjpgdcnf.h) for that block's
 * rectangle. We just copy it into our full-frame buffer at the right
 * offset; the actual panel transform happens after decode is done.
 */
static int jpeg_output_func(JDEC *jd, void *bitmap, JRECT *rect)
{
	ARG_UNUSED(jd);

	const uint16_t *src = (const uint16_t *)bitmap;
	uint16_t block_w = (uint16_t)(rect->right - rect->left + 1);
	uint16_t block_h = (uint16_t)(rect->bottom - rect->top + 1);

	for (uint16_t y = 0; y < block_h; y++) {
		uint16_t dst_row = (uint16_t)(rect->top + y);

		if (dst_row >= DEC_HEIGHT) {
			continue; /* Bottom padding row beyond our framebuffer - ignore. */
		}
		for (uint16_t x = 0; x < block_w; x++) {
			uint16_t dst_col = (uint16_t)(rect->left + x);

			if (dst_col >= DEC_WIDTH) {
				continue; /* Right padding column - ignore. */
			}
			g_decode_fb[(size_t)dst_row * DEC_WIDTH + dst_col] = src[(size_t)y * block_w + x];
		}
	}
	return 1; /* Continue decoding. */
}

/*
 * ---- Rotate + "cover" crop (same geometry as Lab C3) ----
 *
 * The decoded frame (240x135, landscape) and the TFT panel (240x280,
 * portrait) do not share an aspect ratio, so exactly the same
 * rotate-then-cover-crop approach from Lab C3 is reused here - just
 * without the Bayer-block averaging step, since JPEG decoding already
 * produced full, real RGB565 pixels (this still image is shown in
 * actual color, unlike Lab C3's grayscale debayer-lite preview).
 */
static void compute_cover_crop(uint32_t src_w, uint32_t src_h, uint32_t dst_w, uint32_t dst_h,
				uint32_t *crop_x0, uint32_t *crop_y0,
				uint32_t *crop_w, uint32_t *crop_h)
{
	if (src_w * dst_h > src_h * dst_w) {
		*crop_h = src_h;
		*crop_w = src_h * dst_w / dst_h;
	} else {
		*crop_w = src_w;
		*crop_h = src_w * dst_h / dst_w;
	}
	*crop_x0 = (src_w - *crop_w) / 2U;
	*crop_y0 = (src_h - *crop_h) / 2U;
}

/* Maps a pixel in the rotated+cropped view back to its source pixel
 * in the decoded (unrotated) framebuffer. Inverse of a 90 degree
 * clockwise rotation, same as Lab C3's rotate_to_bayer_coords() minus
 * the 2x2 Bayer-grid snapping (not needed - every decoded pixel is
 * already a complete RGB565 value).
 */
static void rotate_to_fb_coords(uint32_t rot_col, uint32_t rot_row, uint32_t *fb_col,
				 uint32_t *fb_row)
{
	uint32_t row_s = (DEC_HEIGHT - 1U) - rot_col;
	uint32_t col_s = rot_row;

	if (row_s >= DEC_HEIGHT) {
		row_s = DEC_HEIGHT - 1U;
	}
	if (col_s >= DEC_WIDTH) {
		col_s = DEC_WIDTH - 1U;
	}

	*fb_col = col_s;
	*fb_row = row_s;
}

static void render_decoded_frame(void)
{
	/* Rotated canvas: decoded frame's width/height swapped. */
	uint32_t rotated_w = DEC_HEIGHT;
	uint32_t rotated_h = DEC_WIDTH;
	uint32_t crop_x0, crop_y0, crop_w, crop_h;
	uint8_t row[PANEL_WIDTH * 2];

	compute_cover_crop(rotated_w, rotated_h, PANEL_WIDTH, PANEL_HEIGHT,
			    &crop_x0, &crop_y0, &crop_w, &crop_h);

	if (st7789_set_addr_window(0, 0, PANEL_WIDTH - 1, PANEL_HEIGHT - 1)) {
		return;
	}

	for (uint16_t oy = 0; oy < PANEL_HEIGHT; oy++) {
		uint32_t rot_row = crop_y0 + (uint32_t)oy * crop_h / PANEL_HEIGHT;

		for (uint16_t ox = 0; ox < PANEL_WIDTH; ox++) {
			uint32_t rot_col = crop_x0 + (uint32_t)ox * crop_w / PANEL_WIDTH;
			uint32_t fx, fy;

			rotate_to_fb_coords(rot_col, rot_row, &fx, &fy);

			uint16_t pixel = g_decode_fb[(size_t)fy * DEC_WIDTH + fx];

			row[ox * 2U] = pixel >> 8;
			row[ox * 2U + 1U] = pixel & 0xFF;
		}

		if (st7789_write_data(row, (size_t)PANEL_WIDTH * 2U)) {
			return;
		}
	}
}

int tft_still_show_jpeg(const uint8_t *jpeg, size_t jpeg_size)
{
	struct jpeg_input_ctx ctx = { .data = jpeg, .size = jpeg_size, .pos = 0 };
	JDEC jd;
	JRESULT jr;

	if (!tft_ready) {
		return -ENODEV;
	}

	jr = jd_prepare(&jd, jpeg_input_func, jd_work, sizeof(jd_work), &ctx);
	if (jr != JDR_OK) {
		printk("tft_still: jd_prepare failed (JRESULT=%d)\n", jr);
		return -(int)jr;
	}

	if (jd.width != (DEC_WIDTH << JD_SCALE) || jd.height != (DEC_HEIGHT << JD_SCALE)) {
		printk("tft_still: unexpected JPEG size %ux%u (expected %ux%u) - showing anyway\n",
		       jd.width, jd.height, DEC_WIDTH << JD_SCALE, DEC_HEIGHT << JD_SCALE);
	}

	memset(g_decode_fb, 0, sizeof(g_decode_fb));

	jr = jd_decomp(&jd, jpeg_output_func, (uint8_t)JD_SCALE);
	if (jr != JDR_OK) {
		printk("tft_still: jd_decomp failed (JRESULT=%d)\n", jr);
		return -(int)jr;
	}

	render_decoded_frame();
	printk("tft_still: JPEG decoded (%ux%u) and shown on panel\n", jd.width, jd.height);
	return 0;
}
```

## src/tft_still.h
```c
/* Lab C4 TFT still-preview helper, built on the same raw-SPI
 * ST7789V3 driver confirmed working in ai_labs/03_sensor_anomaly and
 * Lab C3. Unlike Lab C3 (which pushed a continuous grayscale
 * debayer-lite preview), this pushes a single still image decoded
 * from the JPEG the hardware encoder just produced - a real color
 * image, since JPEG decoding does full chroma reconstruction.
 */
#ifndef TFT_STILL_H_
#define TFT_STILL_H_

#include <stddef.h>
#include <stdint.h>

/* Call once at boot. Safe to call even if the panel/level-shifter
 * isn't connected - failures are logged via printk and
 * tft_still_show_jpeg() is simply left a no-op.
 */
void tft_still_init(void);

/* Decodes a JPEG buffer (as produced by the syna,enc-video hardware
 * encoder) and displays it as a single still image, filling the
 * whole panel (rotated 90 degrees + "cover" cropped exactly like Lab
 * C3 - see the implementation comment in tft_still.c). Expects a
 * 480x270 source JPEG (this lab's fixed capture resolution); returns
 * 0 on success, a negative TJpgDec error code on decode failure, or
 * -ENODEV if tft_still_init() didn't succeed. No-op (return value
 * still meaningful) if the panel isn't ready.
 */
int tft_still_show_jpeg(const uint8_t *jpeg, size_t jpeg_size);

#endif /* TFT_STILL_H_ */
```

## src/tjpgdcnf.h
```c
/*----------------------------------------------*/
/* TJpgDec System Configurations R0.03          */
/*----------------------------------------------*/
/*
 * Lab C4 (TFT still preview) tuning: this decoder is vendored
 * verbatim from ChaN's TJpgDec (see tjpgd.c header for license and
 * version info) except for this configuration file, adjusted so its
 * output format matches what the ST7789V3 panel wants directly
 * (RGB565) instead of the default RGB888 - see tft_still.c.
 */

#define	JD_SZBUF		512
/* Specifies size of stream input buffer */

#define JD_FORMAT		1
/* Specifies output pixel format.
/  0: RGB888 (24-bit/pix)
/  1: RGB565 (16-bit/pix)  <- selected: matches the ST7789V3's native format
/  2: Grayscale (8-bit/pix)
*/

#define	JD_USE_SCALE	1
/* Switches output descaling feature.
/  0: Disable
/  1: Enable  <- selected: lets us decode straight to a half-size
/     (240x135) image instead of the full 480x270, halving both the
/     framebuffer size and the decode work.
*/

#define JD_TBLCLIP		1
/* Use table conversion for saturation arithmetic. A bit faster, but increases 1 KB of code size.
/  0: Disable
/  1: Enable
*/

#define JD_FASTDECODE	0
/* Optimization level
/  0: Basic optimization. Suitable for 8/16-bit MCUs.  <- selected: smallest code size
/  1: + 32-bit barrel shifter. Suitable for 32-bit MCUs.
/  2: + Table conversion for huffman decoding (wants 6 << HUFF_BIT bytes of RAM)
*/
```
